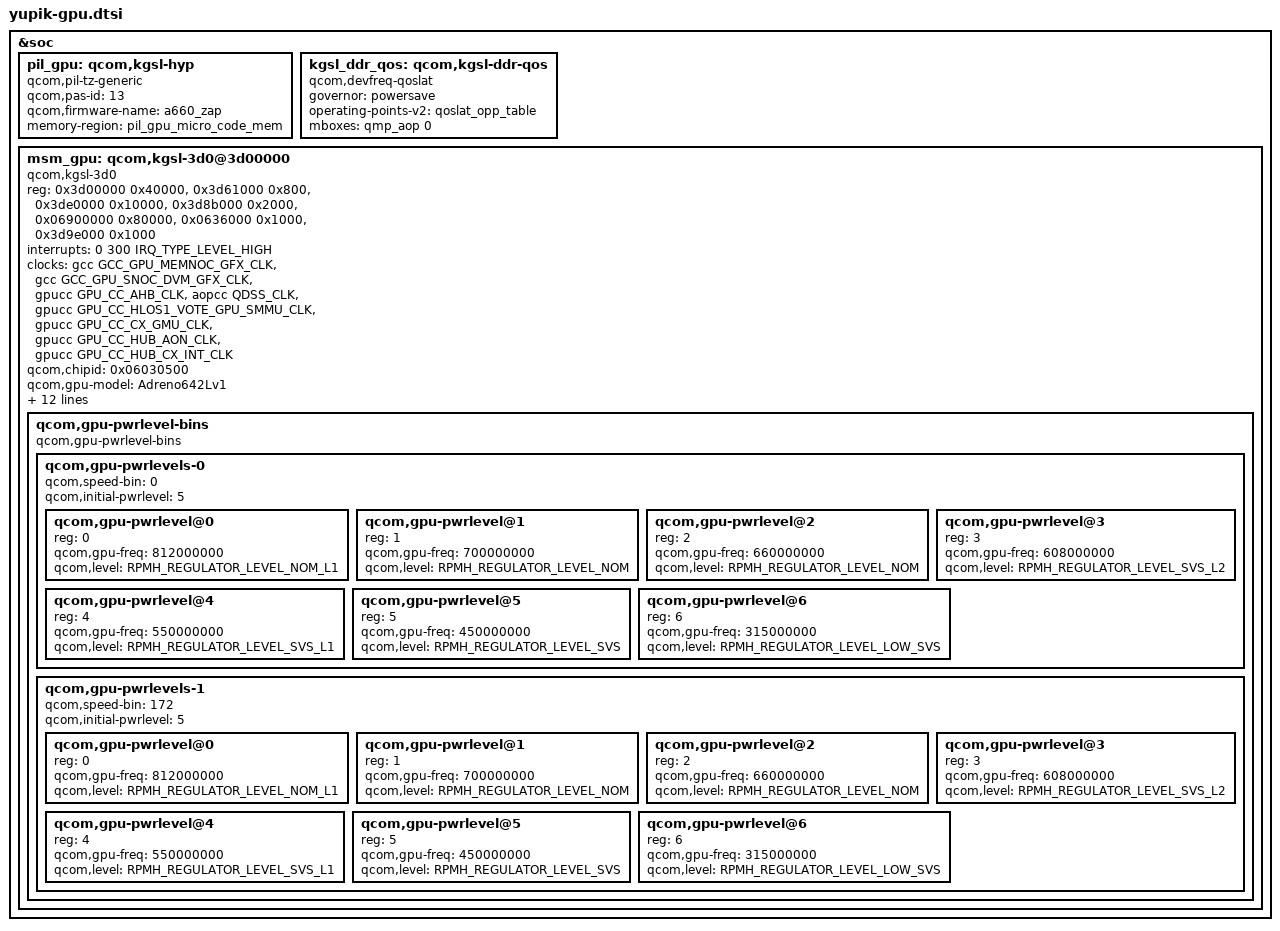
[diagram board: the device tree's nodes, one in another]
#define MHZ_TO_KBPS(mhz, w) ((mhz * 1000000 * w) / (1024))

&soc {
	pil_gpu: qcom,kgsl-hyp {
		compatible = "qcom,pil-tz-generic";
		qcom,pas-id = <13>;
		qcom,firmware-name = "a660_zap";
		memory-region = <&pil_gpu_micro_code_mem>;
	};

	kgsl_ddr_qos: qcom,kgsl-ddr-qos {
		compatible = "qcom,devfreq-qoslat";
		governor = "powersave";
		operating-points-v2 = <&qoslat_opp_table>;
		mboxes = <&qmp_aop 0>;
	};

	msm_gpu: qcom,kgsl-3d0@3d00000 {
		compatible = "qcom,kgsl-3d0",
			"qcom,adreno-gpu-a642l";
		status = "ok";

		reg = <0x3d00000 0x40000>, <0x3d61000 0x800>,
			<0x3de0000 0x10000>, <0x3d8b000 0x2000>,
			<0x06900000 0x80000>, <0x0636000 0x1000>,
			<0x3d9e000 0x1000>;

		reg-names = "kgsl_3d0_reg_memory", "cx_dbgc", "rscc",
			"isense_cntl", "qdss_gfx", "rdpm_mx",
			"cx_misc";

		interrupts = <0 300 IRQ_TYPE_LEVEL_HIGH>;
		interrupt-names = "kgsl_3d0_irq";

		clocks = <&gcc GCC_GPU_MEMNOC_GFX_CLK>,
			<&gcc GCC_GPU_SNOC_DVM_GFX_CLK>,
			<&gpucc GPU_CC_AHB_CLK>,
			<&aopcc QDSS_CLK>,
			<&gpucc GPU_CC_HLOS1_VOTE_GPU_SMMU_CLK>,
			<&gpucc GPU_CC_CX_GMU_CLK>,
			<&gpucc GPU_CC_HUB_AON_CLK>,
			<&gpucc GPU_CC_HUB_CX_INT_CLK>;

		clock-names = "gcc_gpu_memnoc_gfx",
				"gcc_gpu_snoc_dvm_gfx",
				"gpu_cc_ahb",
				"apb_pclk",
				"gpu_cc_hlos1_vote_gpu_smmu",
				"gpu_cc_cx_gmu",
				"gpu_cc_hub_aon",
				"gpu_cc_hub_cx_int";

		qcom,chipid = <0x06030500>;
		qcom,gpu-model = "Adreno642Lv1";
		qcom,no-nap;

		qcom,min-access-length = <32>;
		qcom,ubwc-mode = <3>;

		nvmem-cells = <&gpu_speed_bin>, <&gpu_gaming_bin>, <&gpu_model_bin>;
		nvmem-cell-names = "speed_bin", "gaming_bin", "gpu_model";

		qcom,tzone-names = "gpuss-0-usr", "gpuss-1-usr";

		interconnects = <&gem_noc MASTER_GFX3D &mc_virt SLAVE_EBI1>,
			<&epss_l3_cpu MASTER_EPSS_L3_APPS &epss_l3_cpu SLAVE_EPSS_L3_SHARED>;
		interconnect-names = "gpu_icc_path", "l3_path";

		/* … BUS TABLES MANTIDAS SEM ALTERAÇÃO … */

		qcom,gpu-pwrlevel-bins {
			compatible = "qcom,gpu-pwrlevel-bins";

			qcom,gpu-pwrlevels-0 {
				qcom,speed-bin = <0>;
				qcom,initial-pwrlevel = <5>;

				qcom,gpu-pwrlevel@0 {
					reg = <0>;
					qcom,gpu-freq = <812000000>;
					qcom,level = <RPMH_REGULATOR_LEVEL_NOM_L1>;
				};

				qcom,gpu-pwrlevel@1 {
					reg = <1>;
					qcom,gpu-freq = <700000000>;
					qcom,level = <RPMH_REGULATOR_LEVEL_NOM>;
				};

				qcom,gpu-pwrlevel@2 { /* ADICIONADO */
					reg = <2>;
					qcom,gpu-freq = <660000000>;
					qcom,level = <RPMH_REGULATOR_LEVEL_NOM>;
				};

				qcom,gpu-pwrlevel@3 {
					reg = <3>;
					qcom,gpu-freq = <608000000>;
					qcom,level = <RPMH_REGULATOR_LEVEL_SVS_L2>;
				};

				qcom,gpu-pwrlevel@4 {
					reg = <4>;
					qcom,gpu-freq = <550000000>;
					qcom,level = <RPMH_REGULATOR_LEVEL_SVS_L1>;
				};

				qcom,gpu-pwrlevel@5 {
					reg = <5>;
					qcom,gpu-freq = <450000000>;
					qcom,level = <RPMH_REGULATOR_LEVEL_SVS>;
				};

				qcom,gpu-pwrlevel@6 {
					reg = <6>;
					qcom,gpu-freq = <315000000>;
					qcom,level = <RPMH_REGULATOR_LEVEL_LOW_SVS>;
				};
			};

			qcom,gpu-pwrlevels-1 {
				qcom,speed-bin = <172>;
				qcom,initial-pwrlevel = <5>;

				qcom,gpu-pwrlevel@0 {
					reg = <0>;
					qcom,gpu-freq = <812000000>;
					qcom,level = <RPMH_REGULATOR_LEVEL_NOM_L1>;
				};

				qcom,gpu-pwrlevel@1 {
					reg = <1>;
					qcom,gpu-freq = <700000000>;
					qcom,level = <RPMH_REGULATOR_LEVEL_NOM>;
				};

				qcom,gpu-pwrlevel@2 { /* ADICIONADO */
					reg = <2>;
					qcom,gpu-freq = <660000000>;
					qcom,level = <RPMH_REGULATOR_LEVEL_NOM>;
				};

				qcom,gpu-pwrlevel@3 {
					reg = <3>;
					qcom,gpu-freq = <608000000>;
					qcom,level = <RPMH_REGULATOR_LEVEL_SVS_L2>;
				};

				qcom,gpu-pwrlevel@4 {
					reg = <4>;
					qcom,gpu-freq = <550000000>;
					qcom,level = <RPMH_REGULATOR_LEVEL_SVS_L1>;
				};

				qcom,gpu-pwrlevel@5 {
					reg = <5>;
					qcom,gpu-freq = <450000000>;
					qcom,level = <RPMH_REGULATOR_LEVEL_SVS>;
				};

				qcom,gpu-pwrlevel@6 {
					reg = <6>;
					qcom,gpu-freq = <315000000>;
					qcom,level = <RPMH_REGULATOR_LEVEL_LOW_SVS>;
				};
			};
		};
	};
};
